# R7FA6T3BB register map
Vendor: Renesas Electronics Corporation; Series: RA6; File version: 1.20.00
CPU: CM33 r0p4, little endian, MPU, FPU, VTOR, 4 interrupt priority bits, 96 interrupts
Registers are 32-bit, read-write, reset 0x0 unless marked. A register's access mark holds for its fields unless they carry their own. Offsets are from the block's base; [hi:lo] are bit positions.

## TSN — Temperature Sensor
Base 0x400F3000
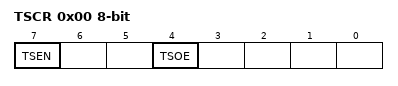
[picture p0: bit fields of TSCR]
0x00 TSCR 8-bit — Temperature Sensor Control Register
  [7] TSEN — Temperature Sensor Enable
    0=Stop the temperature sensor; 1=Start the temperature sensor
  [4] TSOE — Temperature Sensor Output Enable
    0=Disable output from the temperature sensor to the ADC12; 1=Enable output from the temperature sensor to the ADC12

## ACMPHS0 — High-Speed Analog Comparator 0
Base 0x400F4000
Same registers: ACMPHS1 0x400F4100, ACMPHS2 0x400F4200
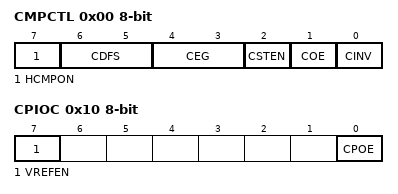
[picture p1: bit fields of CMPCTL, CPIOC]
0x00 CMPCTL 8-bit — Comparator Control Register
  [7] HCMPON — Comparator Operation Control
    0=Stop operation (comparator outputs a low-level signal); 1=Enable operation (enables input to the comparator pins)
  [6:5] CDFS — Noise Filter Selection
    0=Do not use noise filter; 1=Use noise filter sampling frequency of PCLKB/23; 2=Use noise filter sampling frequency of PCLKB/24; 3=Use noise filter sampling frequency of PCLKB/25
  [4:3] CEG — Selection of Valid Edge (Edge Selector)
    0=Do not detect edge; 1=Detect rising edge; 2=Detect falling edge; 3=Detect both edges
  [2] CSTEN — Interrupt Select
    0=Output through the edge selector; 1=Output directly
  [1] COE — Comparator Output Enable
    0=Disable comparator output (output signal is low level); 1=Enable comparator output
  [0] CINV — Comparator Output Polarity Selection
    0=Do not invert comparator output; 1=Invert comparator output
0x04 CMPSEL0 8-bit — Comparator Input Select Register
  [3:0] CMPSEL — Comparator Input Selection
    0=Do not input; 1=Select IVCMP0; 2=Select IVCMP1; 4=Select IVCMP2; 8=Select IVCMP3; other=Others (Setting prohibited)
0x08 CMPSEL1 8-bit — Comparator Reference Voltage Select Register
  [3:0] CRVS — Reference Voltage Selection
    0=Do not input; 1=Select IVREF0; 2=Select IVREF1; 4=Select IVREF2; 8=Select IVREF3; other=Others (Setting prohibited)
0x0C CMPMON 8-bit ro — Comparator Output Monitor Register
  [0] CMPMON — Comparator Output Monitor
    0=Comparator output is low; 1=Comparator output is high
0x10 CPIOC 8-bit — Comparator Output Control Register
  [7] VREFEN — VREFEN Internal Vref Enable
    0=Disable internal Vref; 1=Enable internal Vref
  [0] CPOE — Comparator Output Selection
    0=Disable CMPOUTn pin output of the comparator (output signal is low fixed); 1=Enable CMPOUTn pin output of the comparator

## CRC — Cyclic Redundancy Check Calculator
Base 0x40108000
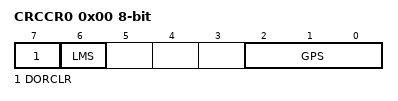
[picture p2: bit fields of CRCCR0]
0x00 CRCCR0 8-bit — CRC Control Register 0
  [7] DORCLR wo — CRCDOR/CRCDOR_HA/CRCDOR_BY Register Clear
    0=No effect; 1=Clear the CRCDOR/CRCDOR_HA/CRCDOR_BY register
  [6] LMS — CRC Calculation Switching
    0=Generate CRC code for LSB-first communication; 1=Generate CRC code for MSB-first communication
  [2:0] GPS — CRC Generating Polynomial Switching
    1=8-bit CRC-8 (X8 + X2 + X + 1); 2=16-bit CRC-16 (X16 + X15 + X2 + 1); 3=16-bit CRC-CCITT (X16 + X12 + X5 + 1); 4=32-bit CRC-32 (X32 + X26 + X23 + X22 + X16 + X12 + X11 +X10 + X8 + X7 + X5 + X4 + X2 + X + 1); 5=32-bit CRC-32C (X32 + X28 + X27 + X26 + X25 + X23 + X22 + X20 + X19 + X18 + X14 + X13 + X11 + X10 + X9 + X8 + X6 + 1); other=Others (No calculation is executed)
0x04 CRCDIR — CRC Data Input Register
0x04 CRCDIR_BY 8-bit (alternate view of CRCDIR) — CRC Data Input Register
0x08 CRCDOR — CRC Data Output Register
0x08 CRCDOR_HA 16-bit (alternate view of CRCDOR) — CRC Data Output Register
0x08 CRCDOR_BY 8-bit (alternate view of CRCDOR) — CRC Data Output Register

## DOC — Data Operation Circuit
Base 0x40109000
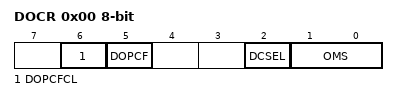
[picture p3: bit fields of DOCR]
0x00 DOCR 8-bit — DOC Control Register
  [6] DOPCFCL — DOPCF Clear
    0=Retain DOPCF flag state; 1=Clear DOPCF flag
  [5] DOPCF ro — DOC Flag
  [2] DCSEL — Detection Condition Select
    0=Set DOPCF flag when data mismatch is detected; 1=Set DOPCF flag when data match is detected
  [1:0] OMS — Operating Mode Select
    0=Data comparison mode; 1=Data addition mode; 2=Data subtraction mode; 3=Setting prohibited
0x02 DODIR 16-bit — DOC Data Input Register
0x04 DODSR 16-bit — DOC Data Setting Register
